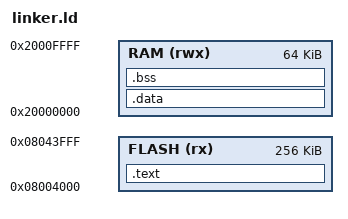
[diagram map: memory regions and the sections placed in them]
MEMORY
{
    FLASH(rx) : ORIGIN = 0x08004000, LENGTH = 256K
    RAM(rwx) : ORIGIN = 0X20000000, LENGTH = 64K
}

SECTIONS
{
    .text :
    {
        KEEP(*(.isr_vector))
        *(.text*)
        *(.rodata*)
        _etext = .;
    } > FLASH

    .data : AT (ADDR(.text) + SIZEOF(.text))
    {
        _sdata = .;
        *(.data*)
        _edata = .;
    } > RAM

    .bss :
    {
        _sbss = .;
        *(.bss*)
        *(COMMON)
        _ebss = .;
    } > RAM
}
